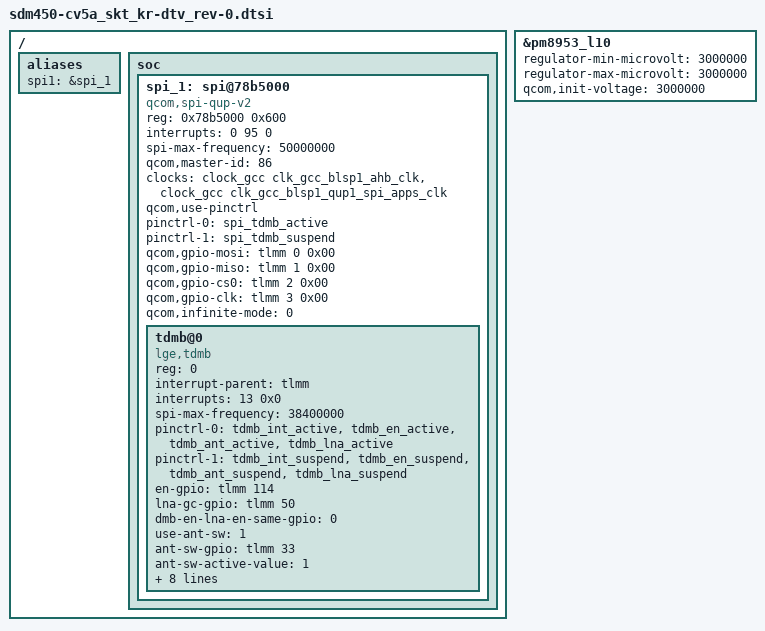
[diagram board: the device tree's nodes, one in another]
/* Copyright (c) 2014, The Linux Foundation. All rights reserved.
 *
 * This program is free software; you can redistribute it and/or modify
 * it under the terms of the GNU General Public License version 2 and
 * only version 2 as published by the Free Software Foundation.
 *
 * This program is distributed in the hope that it will be useful,
 * but WITHOUT ANY WARRANTY; without even the implied warranty of
 * MERCHANTABILITY or FITNESS FOR A PARTICULAR PURPOSE.  See the
 * GNU General Public License for more details.
 */

&pm8953_l10 {
	regulator-min-microvolt = <3000000>;
	regulator-max-microvolt = <3000000>;
	qcom,init-voltage = <3000000>;
	status = "ok";
};

/ {
	aliases {
		spi1 = &spi_1;
	};

	soc {
		spi_1: spi@78b5000 {	// [Modified] QUP_BASE address for BLSP1 QUP1 (ref. AP datasheet, This model use BLSP-1 QUP1)
         /* [1. SPI Information]
          *  1) BLSP #1
          *  2) GPIO #0~3
          */
			status = "ok";
			compatible = "qcom,spi-qup-v2";

			// [Fixed] Address, size for slave chips.
			#address-cells = <1>;
			#size-cells = <0>;

			/* [Fixed] Resister region names referenced in reg.
				"spi_physical"     : Physical address of controller register blocks.
				when use BAM mode, add "spi_bam_physical"
				"spi_bam_physical" : Physical address of BAM controller.
				Keep the same names. */
			reg-names = "spi_physical";

			/* [Modified] Modify the reg field as below to add BLSP BAM base address (ref. AP datasheet)
				First Row is BLSP_QUP base address, size,
				Second Row is BAM address, size. */
			reg = <0x78b5000 0x600> ;

			/* [Fixed] Interrupt resource names referenced in interrupts.
				"spi_irq"     : QUP-core interrupt
				when use BAM mode, add "spi_bam_irq"
				"spi_bam_irq" : BAM interrupt
				Keep the same names. */
			interrupt-names = "spi_irq";

			/* [Modified] Replace the interrupt filed. (ref. AP datasheet)
				First Field  : SPI interrupt, keep 0
				Second Field : Interrupt #
				Third Field  : Trigger type, keep 0
				First Row is BLSP_QUP base, Second Row is BAM. */
			interrupts = <0 95 0>;

			// [Fixed] Specifies maximum SPI clock frequency of AP(50 MHz). (ref. QCT SPI datasheet)
			spi-max-frequency = <50000000>;

			// [Modified] BLSP bus master ID. (ref. AP datasheet)
			qcom,master-id = <86>;

			// [Fixed] Set up the clocks, Keep the same names.
			clock-names = "iface_clk", "core_clk";
			/* [Modified]
				Add node to BLSP# AHB clock,
				Add node to QUP Core clock (BLSP# QUP#)
				Note : In clock QUP Core is label #1 to X. So QUP0 would be label as QUP1. */
			clocks = <&clock_gcc clk_gcc_blsp1_ahb_clk>, <&clock_gcc clk_gcc_blsp1_qup1_spi_apps_clk>;

			// [Fixed] When use pinctrl, enable.
			qcom,use-pinctrl;
			// [Fixed] Must contain "spi_default" and "spi_sleep" if pinctrl is to be used. Keep the same names.
			pinctrl-names = "spi_default","spi_sleep";
			/* [Fixed] List of phandles, each pointing at a pin configuration node within a pin controller.
				The list of names to assign states, List entry 0 defines the name for integer state ID 0... */
			pinctrl-0 = <&spi_tdmb_active>;
			pinctrl-1 = <&spi_tdmb_suspend>;

			/* [Modified] Set SPI GPIO (mosi, miso, cs, clk)
				tlmm is the parent, second # is gpio #, third flag keep it 0. */
			qcom,gpio-mosi = <&tlmm 0 0x00>;
			qcom,gpio-miso = <&tlmm 1 0x00>;
			qcom,gpio-cs0 = <&tlmm 2 0x00>;
			qcom,gpio-clk = <&tlmm 3 0x00>;

			// [Fixed] QUP uses infinite-mode. set zero
			qcom,infinite-mode = <0>;
			// [Fixed] When use BAM mode, enable.
			/*qcom,use-bam;*/
			// [Fixed] Version register exists.
			/*qcom,ver-reg-exists;*/
			// [Modified] Add consumer and producer pipes (ref. AP datasheet)
			/*qcom,bam-consumer-pipe-index = <10>;*/
			/*qcom,bam-producer-pipe-index = <11>;*/
		};
	};
};

&spi_1 {
	tdmb@0 {
		compatible = "lge,tdmb"; // [Fixed] Should be "lge,tdmb".
		reg = <0>;

	/* [GPIO Information]
	*  1) interrupts      (DMB_INT)                       : GPIO #13
	*  2) en-gpio         (DMB_EN)                        : GPIO #114
	*  3) ant-sw-gpio  (DMB_ANT_SW)                :   GPIO #33
	*  4) lna-gc-gpio   (DMB_GAIN_CTRL)           :    GPIO #50
	*  5) lna-en-gpio   (DMB_LNA_EN)                 : GPIO #114 (Concurrently use with DMB_EN)
	*  6) ldo-en-gpio   (DMB_LDO_EN)                : NA	*/

		/* [Fixed] parents's node name ("tlmm" on msm8998) */	
		interrupt-parent = <&tlmm>;
		
		/* [Modified] Set DMB_INT GPIO, first # is gpio #, second flag keep it 0. */
		interrupts = <13 0x0>;

		// [Fixed] Specifies maximum SPI clock frequency of DMB chipset(38.4 MHz). (ref. FC8080 datasheet)
		spi-max-frequency = <38400000>;

		/* [Fixed] The list of names to assign states, List entry 0,1,2... define the name for integer state ID 0,1,2...
			- tdmb_pin_active : set to pinctrl-0 list (set to active)
			- tdmb_pin_sleep : set to pinctrl-1 list (set to sleep) 	*/
		pinctrl-names = "tdmb_pin_active", "tdmb_pin_sleep";

		/* [Modified] The pin cofig lists can be for control pin.
			- pinctrl-0 : active state
			- pinctrl-1 : active sleep(suspend)
			The pin config lists shall be defined in the "(model)-pinctrl.dtsi" file
			The control pins lists are interrupt(tdmb_int), enable(tdmb_en),
				FM/DMB antenna swtiching(tdmb_ant), LNA gain control & enable(tdmb_lna), LDO enable(tdmb_lna_en)
			Additional items may vary depending on model schematic. */
		pinctrl-0 = <&tdmb_int_active>, <&tdmb_en_active>, <&tdmb_ant_active>, <&tdmb_lna_active>;
		pinctrl-1 = <&tdmb_int_suspend>, <&tdmb_en_suspend>, <&tdmb_ant_suspend>, <&tdmb_lna_suspend>;
		
		/* [Modified] first is parents's node, second # is gpio #, third flag keep it 0. */
		en-gpio = <&tlmm 114 0x00>;
		lna-gc-gpio = <&tlmm 50 0x00>;
		//lna-en-gpio = <&tlmm ?? 0>;
		//ldo-en-gpio = <&tlmm ?? 0>;
		
		/* [Modified] when use DMB_EN & LDO_EN same gpio, change below property to 1 */
		dmb-en-lna-en-same-gpio = <0>;

	/* [ANT Switch Information]
	*  1) FM/DMB Switch                               : Control
	*  2) TDMB ANT connected to port1 (High) and FM_ANT connected to port2 (Low), so active mode is high
	*/		
		
	/* [Modified] when use ant switching, change use-ant-sw to 1, and set ant active mode (high(1) or low(0)), ant-gpio.
		ant-sw-apio should be dmb_ant's Gpio number */
		use-ant-sw = <1>;
		ant-sw-gpio = <&tlmm 33 0x00>;
		ant-sw-active-value = <1>;

	/* [CLK Information] */
	/* [Modified] when use pmic clk buffer, change use-xtal to 0 and set xtal-freq(DMB Chipset Core clk), interface-freq(SPI interface clk) inter value in kHz. */
		use-xtal = <0>;
        xtal-freq = <19200>;
        interface-freq = <19200>;

	/* [Modified] when using clock buffer, you should check which clock buffer used for dmb device */
		clock-names = "tdmb_xo";
		clocks = <&clock_gcc clk_rf_clk2>;


	/* [Power Supply Description Information]
	*  1) ANT-SW LDO     (PM8953_L10)                 : V3.0, Not always power, power on/off control need
	*  2) DMB LDO      (PM8953_L5)                   : V1.8, always power, power on/off control do not need
	*  3) LNA LDO      (PM8953_L5)                   : V1.8, always power, power on/off control do not need
	*/

	/* [Modified] When use ldo for RFSW, change ctrl-ant-sw-ldo to 1, and ant-sw-supply set the appropriate chipset & power function such as <&pm8953_l10>
				If no use case, change ctrl-ant-sw-ldo to 0, and ant-sw-supply set such as <&chipset#_l??>*/
		ctrl-ant-sw-ldo = <1>;
		ant-sw-ldo-supply = <&pm8953_l10>;

	/* [Modified] when use ldo for LDO_IN, change ctrl-dmb-ldo to 1, and dmb-ldo-supply set the appropriate chipset & power function such as <&pm8953_l10>
				If no use case, change ctrl-dmb-ldo to 0, and dmb-ldo-supply set such as <&chipset#_l??>*/
		ctrl-dmb-ldo = <0>;
		//dmb-ldo-supply = <&chipset#_l??>;

	/* [Modified] when use ldo for LNA(U1800), change ctrl-lna-ldo to 1, and lna-ldo-supply set the appropriate chipset & power function such as <&pm8953_l10>
				If no use case, change ctrl-lna-ldo to 0, and lna-ldo-supply set such as <&chipset#_l??>*/
		ctrl-lna-ldo = <0>;
		//lna-ldo-supply = <&chipset#_l??>;		
	};
};
